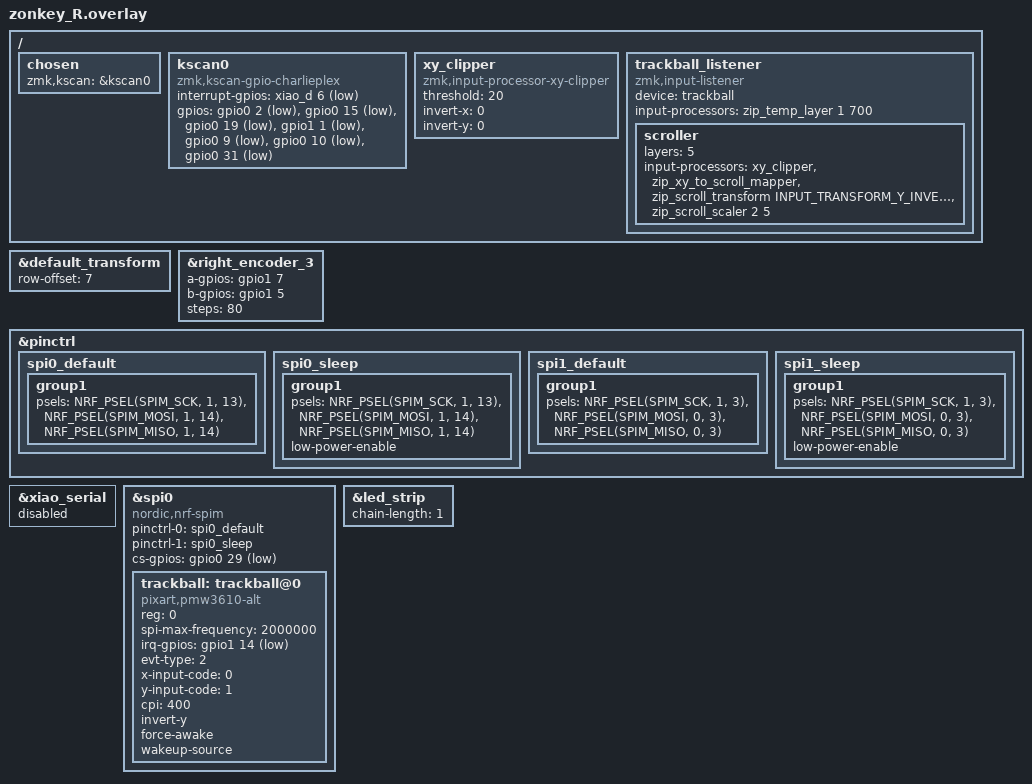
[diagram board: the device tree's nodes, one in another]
#include "zonkey.dtsi"
#include <dt-bindings/zmk/input_transform.h>
#include <dt-bindings/input/input-event-codes.h>
#include <input/processors.dtsi>

/ {
    /* すべてのノード定義は、このルートノード { } の中に記述します */

    chosen {
        // チャーリープレックスの入力機構を最優先で有効化
        zmk,kscan = &kscan0;
    };

    kscan0: kscan0 {
        compatible = "zmk,kscan-gpio-charlieplex";
        interrupt-gpios = <&xiao_d 6 (GPIO_ACTIVE_LOW | GPIO_PULL_UP)>;
        
        // 【タイポ修正完了】コメントの崩れを直し、正常な配列として閉じています
        // ※ 実際の回路の空きピン（例として割り当てていたgpio0 2）を配線に合わせて確定させてください
        gpios = <&gpio0 2  (GPIO_ACTIVE_LOW | GPIO_PULL_UP)>,
                <&gpio0 15 (GPIO_ACTIVE_LOW | GPIO_PULL_UP)>,
                <&gpio0 19 (GPIO_ACTIVE_LOW | GPIO_PULL_UP)>,
                <&gpio1 1  (GPIO_ACTIVE_LOW | GPIO_PULL_UP)>,
                <&gpio0 9  (GPIO_ACTIVE_LOW | GPIO_PULL_UP)>, 
                <&gpio0 10 (GPIO_ACTIVE_LOW | GPIO_PULL_UP)>,
                <&gpio0 31 (GPIO_ACTIVE_LOW | GPIO_PULL_UP)>;
    };

    xy_clipper: xy_clipper {
        compatible = "zmk,input-processor-xy-clipper";
        #input-processor-cells = <0>;
        threshold = <20>;
        invert-x = <0>;
        invert-y = <0>;
    };

    trackball_listener {
        status = "okay";
        compatible = "zmk,input-listener";
        device = <&trackball>;
        input-processors = <&zip_temp_layer 1 700>;

        scroller {
            layers = <5>;
            input-processors =
                <&xy_clipper>,
                <&zip_xy_to_scroll_mapper>,
                <&zip_scroll_transform INPUT_TRANSFORM_Y_INVERT>,
                <&zip_scroll_scaler 2 5>;
        };
    };
}; // ← ここでルートノードを正常に閉じているため、55行目エラーは発生しません

/* ルートの外側は「既存ノードの拡張（&で始まるもの）」のみを記述 */

&default_transform {
    // チャーリープレックスの左右分割位置調整用に row-offset を適用
    row-offset = <7>;
};

&right_encoder_3 {
    a-gpios = <&gpio1 7 (GPIO_ACTIVE_HIGH | GPIO_PULL_UP)>;
    b-gpios = <&gpio1 5 (GPIO_ACTIVE_HIGH | GPIO_PULL_UP)>;
    steps = <80>;
    status = "okay";
};

&pinctrl {
    spi0_default: spi0_default {
        group1 {
            psels = <NRF_PSEL(SPIM_SCK, 1, 13)>,
                    <NRF_PSEL(SPIM_MOSI, 1, 14)>,
                    <NRF_PSEL(SPIM_MISO, 1, 14)>;
        };
    };
    spi0_sleep: spi0_sleep {
        group1 {
            psels = <NRF_PSEL(SPIM_SCK, 1, 13)>,
                    <NRF_PSEL(SPIM_MOSI, 1, 14)>,
                    <NRF_PSEL(SPIM_MISO, 1, 14)>;
            low-power-enable;
        };
    };
    spi1_default: spi1_default {
        group1 {
            psels = <NRF_PSEL(SPIM_SCK, 1, 3)>,
                    <NRF_PSEL(SPIM_MOSI, 0, 3)>,
                    <NRF_PSEL(SPIM_MISO, 0, 3)>;
        };
    };
    spi1_sleep: spi1_sleep {
        group1 {
            psels = <NRF_PSEL(SPIM_SCK, 1, 3)>,
                    <NRF_PSEL(SPIM_MOSI, 0, 3)>,
                    <NRF_PSEL(SPIM_MISO, 0, 3)>;
            low-power-enable;
        };
    };
};

&xiao_serial { status = "disabled"; };

&spi0 {
    status = "okay";
    compatible = "nordic,nrf-spim";
    pinctrl-0 = <&spi0_default>;
    pinctrl-1 = <&spi0_sleep>;
    pinctrl-names = "default", "sleep";
    cs-gpios = <&gpio0 29 GPIO_ACTIVE_LOW>; // トラックボールの独立CS

    trackball: trackball@0 {
        status = "okay";
        compatible = "pixart,pmw3610-alt";
        reg = <0>;
        spi-max-frequency = <2000000>;
        irq-gpios = <&gpio1 14 (GPIO_ACTIVE_LOW | GPIO_PULL_UP)>;
        evt-type = <2>;
        x-input-code = <0>;
        y-input-code = <1>;
        cpi = <400>;
        invert-y;
        force-awake;
        wakeup-source;
    };
};

&led_strip {
    status = "okay";
    chain-length = <1>;
};
